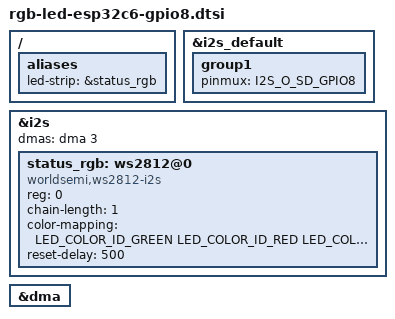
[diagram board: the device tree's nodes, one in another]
/* SPDX-License-Identifier: Apache-2.0
 *
 * Status LED: the WS2812 addressable RGB LED on GPIO8 of ESP32-C6-DevKitC
 * boards (and the clone tested here), driven by the I2S peripheral as in
 * Zephyr's led_strip sample. lib/common/status_led.c uses the `led-strip`
 * alias when the board has no plain `led0`.
 */
#include <zephyr/dt-bindings/led/led.h>

/ {
	aliases {
		led-strip = &status_rgb;
	};
};

&i2s_default {
	group1 {
		pinmux = <I2S_O_SD_GPIO8>;
	};
};

&i2s {
	status = "okay";
	dmas = <&dma 3>;
	dma-names = "tx";

	status_rgb: ws2812@0 {
		compatible = "worldsemi,ws2812-i2s";
		reg = <0>;
		chain-length = <1>;
		color-mapping = <LED_COLOR_ID_GREEN
				 LED_COLOR_ID_RED
				 LED_COLOR_ID_BLUE>;
		reset-delay = <500>;
	};
};

&dma {
	status = "okay";
};
